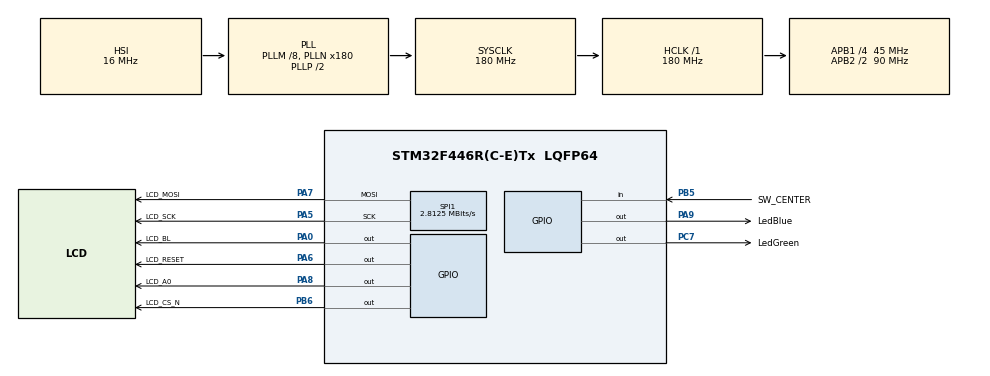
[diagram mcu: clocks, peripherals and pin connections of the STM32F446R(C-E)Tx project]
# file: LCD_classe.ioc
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Mcu.Family=STM32F4
Mcu.Name=STM32F446R(C-E)Tx
Mcu.Package=LQFP64
NVIC.PriorityGroup=NVIC_PRIORITYGROUP_4
PA0-WKUP.GPIO_Label=LCD_BL
PA0-WKUP.Signal=GPIO_Output
PA13.Mode=Serial_Wire
PA13.Signal=SYS_JTMS-SWDIO
PA14.Mode=Serial_Wire
PA14.Signal=SYS_JTCK-SWCLK
PA5.GPIO_Label=LCD_SCK
PA5.Mode=TX_Only_Simplex_Unidirect_Master
PA5.Signal=SPI1_SCK
PA6.GPIO_Label=LCD_RESET
PA6.Signal=GPIO_Output
PA7.GPIO_Label=LCD_MOSI
PA7.Mode=TX_Only_Simplex_Unidirect_Master
PA7.Signal=SPI1_MOSI
PA8.GPIO_Label=LCD_A0
PA8.Signal=GPIO_Output
PA9.GPIO_Label=LedBlue
PA9.GPIO_Speed=GPIO_SPEED_FREQ_HIGH
PA9.PinState=GPIO_PIN_RESET
PA9.Signal=GPIO_Output
PB5.GPIO_Label=SW_CENTER
PB5.Signal=GPIO_Input
PB6.GPIO_Label=LCD_CS_N
PB6.Signal=GPIO_Output
PC7.GPIO_Label=LedGreen
PC7.Signal=GPIO_Output
PH0-OSC_IN.Mode=HSE-External-Oscillator
PH0-OSC_IN.Signal=RCC_OSC_IN
PH1-OSC_OUT.Mode=HSE-External-Oscillator
PH1-OSC_OUT.Signal=RCC_OSC_OUT
ProjectManager.HeapSize=0x200
ProjectManager.StackSize=0x400
ProjectManager.TargetToolchain=MDK-ARM V5
RCC.AHBFreq_Value=180000000
RCC.APB1CLKDivider=RCC_HCLK_DIV4
RCC.APB1Freq_Value=45000000
RCC.APB1TimFreq_Value=90000000
RCC.APB2CLKDivider=RCC_HCLK_DIV2
RCC.APB2Freq_Value=90000000
RCC.APB2TimFreq_Value=180000000
RCC.CortexFreq_Value=180000000
RCC.HCLKFreq_Value=180000000
RCC.PLLM=8
RCC.PLLN=180
RCC.SYSCLKFreq_VALUE=180000000
RCC.SYSCLKSource=RCC_SYSCLKSOURCE_PLLCLK
RCC.USBFreq_Value=180000000
RCC.VCOOutputFreq_Value=360000000
SPI1.BaudRatePrescaler=SPI_BAUDRATEPRESCALER_32
SPI1.CalculateBaudRate=2.8125 MBits/s
SPI1.Direction=SPI_DIRECTION_2LINES
SPI1.Mode=SPI_MODE_MASTER
SPI1.VirtualType=VM_MASTER
board=custom

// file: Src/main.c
/**
  ******************************************************************************
  * @file           : main.c
  * @brief          : Main program body
  ******************************************************************************
  ** This notice applies to any and all portions of this file
  * that are not between comment pairs USER CODE BEGIN and
  * USER CODE END. Other portions of this file, whether
  * inserted by the user or by software development tools
  * are owned by their respective copyright owners.
  *
  * COPYRIGHT(c) 2018 STMicroelectronics
  *
  * Redistribution and use in source and binary forms, with or without modification,
  * are permitted provided that the following conditions are met:
  *   1. Redistributions of source code must retain the above copyright notice,
  *      this list of conditions and the following disclaimer.
  *   2. Redistributions in binary form must reproduce the above copyright notice,
  *      this list of conditions and the following disclaimer in the documentation
  *      and/or other materials provided with the distribution.
  *   3. Neither the name of STMicroelectronics nor the names of its contributors
  *      may be used to endorse or promote products derived from this software
  *      without specific prior written permission.
  *
  * THIS SOFTWARE IS PROVIDED BY THE COPYRIGHT HOLDERS AND CONTRIBUTORS "AS IS"
  * AND ANY EXPRESS OR IMPLIED WARRANTIES, INCLUDING, BUT NOT LIMITED TO, THE
  * IMPLIED WARRANTIES OF MERCHANTABILITY AND FITNESS FOR A PARTICULAR PURPOSE ARE
  * DISCLAIMED. IN NO EVENT SHALL THE COPYRIGHT HOLDER OR CONTRIBUTORS BE LIABLE
  * FOR ANY DIRECT, INDIRECT, INCIDENTAL, SPECIAL, EXEMPLARY, OR CONSEQUENTIAL
  * DAMAGES (INCLUDING, BUT NOT LIMITED TO, PROCUREMENT OF SUBSTITUTE GOODS OR
  * SERVICES; LOSS OF USE, DATA, OR PROFITS; OR BUSINESS INTERRUPTION) HOWEVER
  * CAUSED AND ON ANY THEORY OF LIABILITY, WHETHER IN CONTRACT, STRICT LIABILITY,
  * OR TORT (INCLUDING NEGLIGENCE OR OTHERWISE) ARISING IN ANY WAY OUT OF THE USE
  * OF THIS SOFTWARE, EVEN IF ADVISED OF THE POSSIBILITY OF SUCH DAMAGE.
  *
  ******************************************************************************
  */
#include "main.h"
#include "stm32f4xx_hal.h"
#include "spi.h"
#include "gpio.h"
#include "lcd_driver.h"
#include <stdbool.h>
#include <stdio.h>

/* USER CODE BEGIN PV */
/* Private variables ---------------------------------------------------------*/

/* USER CODE END PV */

void SystemClock_Config(void);

/* USER CODE BEGIN PFP */
/* Private function prototypes -----------------------------------------------*/

/* USER CODE END PFP */

/**
  * @brief  That is Justing more un test about Doc application entry point.
  *
  * @retval None
  */
	/**
	* @warning TEST Warningwhile
	*
	*/
int main(void)
{

  /* MCU Configuration----------------------------------------------------------*/

  /* Reset of all peripherals, Initializes the Flash interface and the Systick. */
  HAL_Init();

  /* Configure the system clock */
  SystemClock_Config();

  /* Initialize all configured peripherals */
  MX_GPIO_Init();
  MX_SPI1_Init();

  /* Infinite loop */
  /* USER CODE BEGIN WHILE */
	lcd_init ();
	//t1=msTicks;
	lcd_clear();
	lcd_setLine(127,0,127,31,1);
	lcd_setLine(0,0,0,31,1);
	lcd_setString(2,6," Welcome ",0,false);
	lcd_show();

  while (1)
  {
		sendData(0xa5);
		 HAL_Delay(100);

  /* USER CODE END WHILE */

  }

}

void SystemClock_Config(void)
{

  RCC_OscInitTypeDef RCC_OscInitStruct;
  RCC_ClkInitTypeDef RCC_ClkInitStruct;

    /**Configure the main internal regulator output voltage
    */
  __HAL_RCC_PWR_CLK_ENABLE();

  __HAL_PWR_VOLTAGESCALING_CONFIG(PWR_REGULATOR_VOLTAGE_SCALE1);

    /**Initializes the CPU, AHB and APB busses clocks
    */
  RCC_OscInitStruct.OscillatorType = RCC_OSCILLATORTYPE_HSI;
  RCC_OscInitStruct.HSIState = RCC_HSI_ON;
  RCC_OscInitStruct.HSICalibrationValue = 16;
  RCC_OscInitStruct.PLL.PLLState = RCC_PLL_ON;
  RCC_OscInitStruct.PLL.PLLSource = RCC_PLLSOURCE_HSI;
  RCC_OscInitStruct.PLL.PLLM = 8;
  RCC_OscInitStruct.PLL.PLLN = 180;
  RCC_OscInitStruct.PLL.PLLP = RCC_PLLP_DIV2;
  RCC_OscInitStruct.PLL.PLLQ = 2;
  RCC_OscInitStruct.PLL.PLLR = 2;
  if (HAL_RCC_OscConfig(&RCC_OscInitStruct) != HAL_OK)
  {
    _Error_Handler(__FILE__, __LINE__);
  }

    /**Activate the Over-Drive mode
    */
  if (HAL_PWREx_EnableOverDrive() != HAL_OK)
  {
    _Error_Handler(__FILE__, __LINE__);
  }

    /**Initializes the CPU, AHB and APB busses clocks
    */
  RCC_ClkInitStruct.ClockType = RCC_CLOCKTYPE_HCLK|RCC_CLOCKTYPE_SYSCLK
                              |RCC_CLOCKTYPE_PCLK1|RCC_CLOCKTYPE_PCLK2;
  RCC_ClkInitStruct.SYSCLKSource = RCC_SYSCLKSOURCE_PLLCLK;
  RCC_ClkInitStruct.AHBCLKDivider = RCC_SYSCLK_DIV1;
  RCC_ClkInitStruct.APB1CLKDivider = RCC_HCLK_DIV4;
  RCC_ClkInitStruct.APB2CLKDivider = RCC_HCLK_DIV2;

  if (HAL_RCC_ClockConfig(&RCC_ClkInitStruct, FLASH_LATENCY_5) != HAL_OK)
  {
    _Error_Handler(__FILE__, __LINE__);
  }

    /**Configure the Systick interrupt time
    */
  HAL_SYSTICK_Config(HAL_RCC_GetHCLKFreq()/1000);

    /**Configure the Systick
    */
  HAL_SYSTICK_CLKSourceConfig(SYSTICK_CLKSOURCE_HCLK);

  /* SysTick_IRQn interrupt configuration */
  HAL_NVIC_SetPriority(SysTick_IRQn, 0, 0);
}

void _Error_Handler(char *file, int line)
{
  while(1)
  {
  }
}

/************************ (C) COPYRIGHT STMicroelectronics *****END OF FILE****/
